# STM32F3x8 register map
File version: 1.5
CPU: CM4 r1p0, little endian, no MPU, no FPU, 3 interrupt priority bits
Registers are 32-bit, read-write, reset 0x0 unless marked. A register's access mark holds for its fields unless they carry their own. Offsets are from the block's base; [hi:lo] are bit positions; lines under a group give offsets from that group; {n}, {i} and the like mark numbered series.

## SDADC1 — Sigma-delta analog-to-digital converter
Base 0x40016000
Same registers: SDADC2 0x40016400, SDADC3 0x40016800
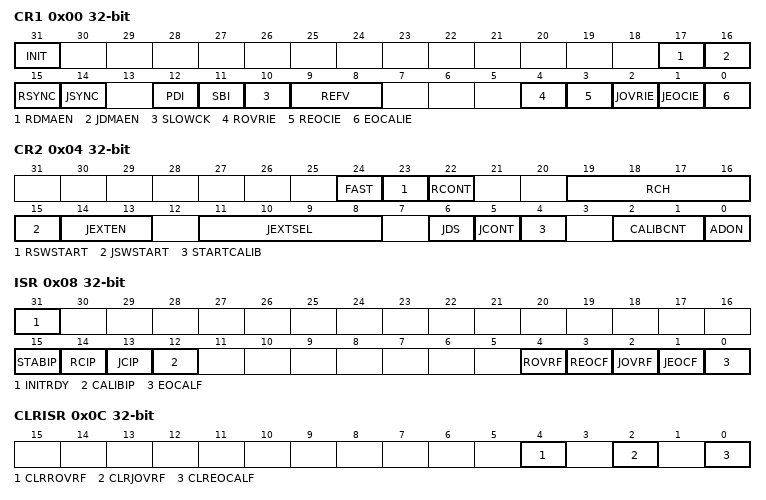
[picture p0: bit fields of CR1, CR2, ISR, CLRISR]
0x00 CR1 — control register 1
  [31] INIT — Initialization mode request
  [17] RDMAEN — DMA channel enabled to read data for the regular channel
  [16] JDMAEN — DMA channel enabled to read data for the injected channel group
  [15] RSYNC — Launch regular conversion synchronously with SDADC1
  [14] JSYNC — Launch a injected conversion synchronously with SDADC1
  [12] PDI — Enter power down mode when idle
  [11] SBI — Enter Standby mode when idle
  [10] SLOWCK — Slow clock mode enable
  [9:8] REFV — Reference voltage selection
  [4] ROVRIE — Regular data overrun interrupt enable
  [3] REOCIE — Regular end of conversion interrupt enable
  [2] JOVRIE — Injected data overrun interrupt enable
  [1] JEOCIE — Injected end of conversion interrupt enable
  [0] EOCALIE — End of calibration interrupt enable
0x04 CR2 — control register 2
  [24] FAST — Fast conversion mode selection
  [23] RSWSTART — Software start of a conversion on the regular channel
  [22] RCONT — Continuous mode selection for regular conversions
  [19:16] RCH — Regular channel selection
  [15] JSWSTART — Start a conversion of the injected group of channels
  [14:13] JEXTEN — Trigger enable and trigger edge selection for injected conversions
  [11:8] JEXTSEL — Trigger signal selection for launching injected conversions
  [6] JDS — Delay start of injected conversions.
  [5] JCONT — Continuous mode selection for injected conversions
  [4] STARTCALIB — Start calibration
  [2:1] CALIBCNT — Number of calibration sequences to be performed (number of valid configurations)
  [0] ADON — SDADC enable
0x08 ISR ro — interrupt and status register
  [31] INITRDY — Initialization mode is ready
  [15] STABIP — Stabilization in progress status
  [14] RCIP — Regular conversion in progress status
  [13] JCIP — Injected conversion in progress status
  [12] CALIBIP — Calibration in progress status
  [4] ROVRF — Regular conversion overrun flag
  [3] REOCF — End of regular conversion flag
  [2] JOVRF — Injected conversion overrun flag
  [1] JEOCF — End of injected conversion flag
  [0] EOCALF — End of calibration flag
0x0C CLRISR — interrupt and status clear register
  [4] CLRROVRF — Clear the regular conversion overrun flag
  [2] CLRJOVRF — Clear the injected conversion overrun flag
  [0] CLREOCALF — Clear the end of calibration flag
0x14 JCHGR reset 0x1 — injected channel group selection register
  [8:0] JCHG — Injected channel group selection
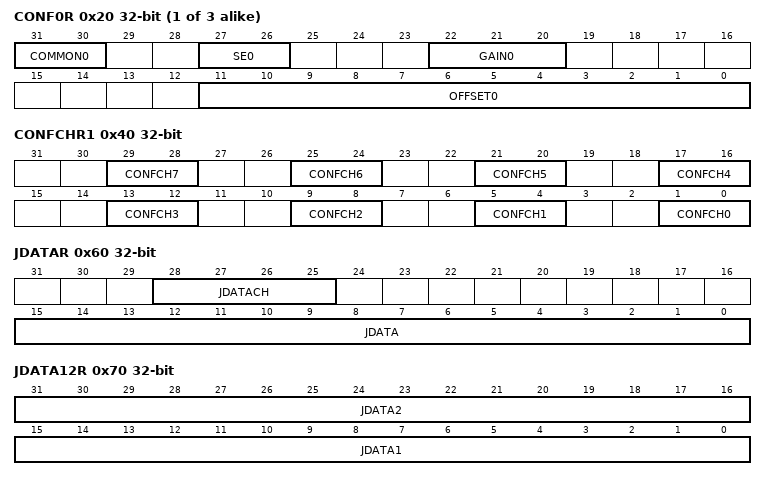
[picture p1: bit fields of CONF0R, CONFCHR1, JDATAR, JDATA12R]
{0x20+4i} CONF{i}R (i=0..2) — configuration {i} register
  [31:30] COMMON{i} — Common mode for configuration {i}
  [27:26] SE{i} — Single-ended mode for configuration {i}
  [22:20] GAIN{i} — Gain setting for configuration {i}
  [11:0] OFFSET{i} — Twelve-bit calibration offset for configuration {i}
0x40 CONFCHR1 — channel configuration register 1
  [4n+1:4n] CONFCH{n} (n=0..7)
0x44 CONFCHR2 — channel configuration register 2
  [1:0] CONFCH8 — Channel 8 configuration
0x60 JDATAR ro — data register for injected group
  [28:25] JDATACH — Injected channel most recently converted
  [15:0] JDATA — Injected group conversion data
0x64 RDATAR ro — data register for the regular channel
  [15:0] RDATA — Regular channel conversion data
0x70 JDATA12R ro — SDADC1 and SDADC2 injected data register
  [31:16] JDATA2 — Injected group conversion data for SDADC2
  [15:0] JDATA1 — Injected group conversion data for SDADC1
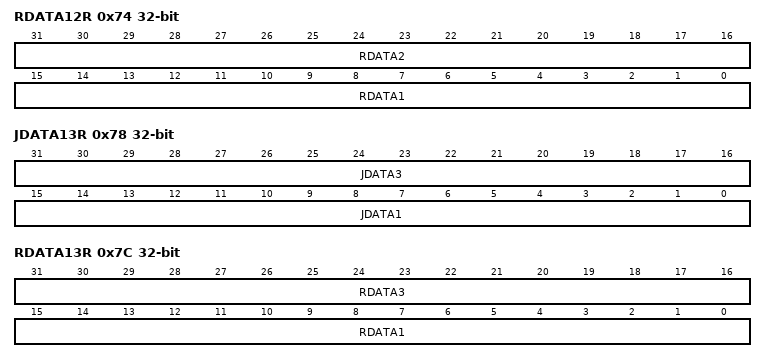
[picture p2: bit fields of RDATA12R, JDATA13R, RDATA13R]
0x74 RDATA12R ro — SDADC1 and SDADC2 regular data register
  [31:16] RDATA2 — Regular conversion data for SDADC2
  [15:0] RDATA1 — Regular conversion data for SDADC1
0x78 JDATA13R ro — SDADC1 and SDADC3 injected data register
  [31:16] JDATA3 — Injected group conversion data for SDADC3
  [15:0] JDATA1 — Injected group conversion data for SDADC1
0x7C RDATA13R ro — SDADC1 and SDADC3 regular data register
  [31:16] RDATA3 — Regular conversion data for SDADC3
  [15:0] RDATA1 — Regular conversion data for SDADC1
